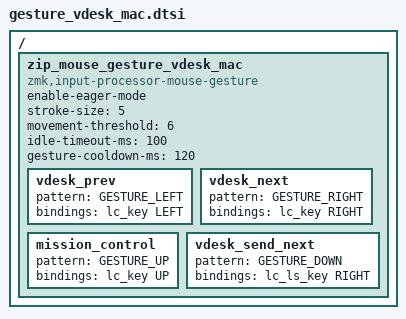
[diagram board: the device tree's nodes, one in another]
/ {
  zip_mouse_gesture_vdesk_mac: zip_mouse_gesture_vdesk_mac {
    compatible = "zmk,input-processor-mouse-gesture";
    #input-processor-cells = <0>;
    enable-eager-mode;
    stroke-size = <5>;
    movement-threshold = <6>;
    idle-timeout-ms = <100>;
    gesture-cooldown-ms = <120>;

    vdesk_prev      { pattern = <GESTURE_LEFT>;  bindings = <&lc_key LEFT>;     };  // 前のSpace Ctrl+←
    vdesk_next      { pattern = <GESTURE_RIGHT>; bindings = <&lc_key RIGHT>;    };  // 次のSpace Ctrl+→
    mission_control { pattern = <GESTURE_UP>;    bindings = <&lc_key UP>;       };  // Mission Control Ctrl+↑
    vdesk_send_next { pattern = <GESTURE_DOWN>;  bindings = <&lc_ls_key RIGHT>; };  // Spaceへ送る Ctrl+Shift+→
  };
};
